# DWC_USB3 register map
Vendor: Texas Instruments
Peripheral module from a debugger description file (folder omap5430_ES2_PUBLIC).
Registers are 32-bit, read-write, reset 0x0 unless marked. A register's access mark holds for its fields unless they carry their own. Offsets are as the file gives them; lines under a group give offsets from that group; [hi:lo] are bit positions; {n}, {i} and the like mark numbered series; 'fields as' and 'values as' point back to an identical list; <NAME> marks a mode.

## DWC_USB3 (part 1 of 2)
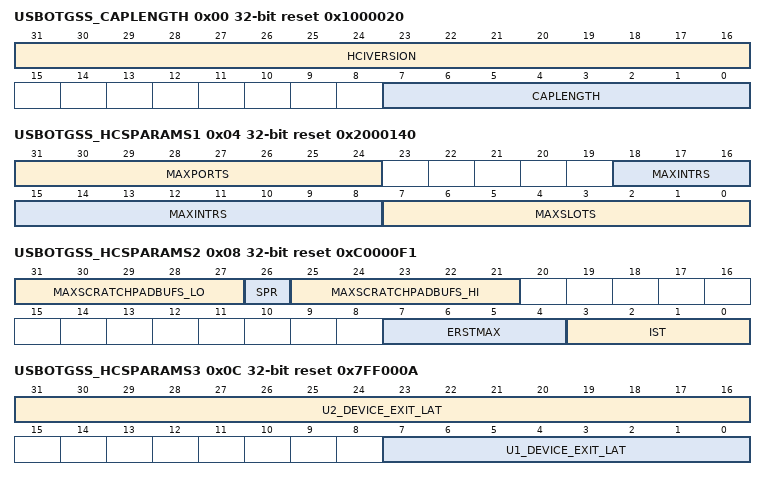
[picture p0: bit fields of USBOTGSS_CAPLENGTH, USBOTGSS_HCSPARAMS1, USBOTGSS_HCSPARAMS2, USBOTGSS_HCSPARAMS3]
0x00 USBOTGSS_CAPLENGTH ro reset 0x1000020 — Capability registers length + host controller interface (HCI) version number
  [31:16] HCIVERSION — Host Controller Interface Version (xHCI), in BCD. Set by USBOTGSS_FLADJ[29] XHCI_REVISION field.
    150=HCIVERSION_150_r (xHCI revision 0.96); 0x100=HCIVERSION_256_r (xHCI revision 1.0 + errata)
  [7:0] CAPLENGTH — Capability Register Length: length of the xHCI Capabilities registers bank, in bytes; also the offset of the xHCI Operational registers bank (starting withUSBOTGSS_USBCMD), with respect to xHCI base (i.e. the current register)
0x04 USBOTGSS_HCSPARAMS1 ro reset 0x2000140 — Host controller structural parameters 1 (xHCI)
  [31:24] MAXPORTS — See xHCI specification.
  [18:8] MAXINTRS — See xHCI specification.
  [7:0] MAXSLOTS — See xHCI specification.
0x08 USBOTGSS_HCSPARAMS2 ro reset 0xC0000F1 — Host controller structural parameters 2 (xHCI)
  [31:27] MAXSCRATCHPADBUFS_LO — Max Scratchpad Buffers, lower bits: See xHCI specification
  [26] SPR — Scratchpad Restore: See xHCI specification
    1=yes (Integrity of the scratchpad buffer required across power events); 0=no (Scratchpad buffers may be freed and reallocated between power events)
  [25:21] MAXSCRATCHPADBUFS_HI — Max Scratchpad Buffers, higher bits: see xHCI 1.0 standard
  [7:4] ERSTMAX — Event Ring Segment Table Max: See xHCI specification
  [3:0] IST — Isochronous Scheduling Threshold: See xHCI specification
0x0C USBOTGSS_HCSPARAMS3 ro reset 0x7FF000A — Host controller structural parameters 3 (xHCI)
  [31:16] U2_DEVICE_EXIT_LAT — U2 device exit latency: Worst-case latency to transition from U2 to U0, in µs. Applies to all root hub ports.
    0x7FF=U2_DEVICE_EXIT_LAT_2047_r (Less than 2047 µs (maximum: Greater values are reserved.)); 2=Less_than_2_µs; 1=Less_than_1_µs; 0=U2_DEVICE_EXIT_LAT_0_r (0)
  [7:0] U1_DEVICE_EXIT_LAT — U1 device exit latency: Worst-case latency to transition a root hub port link state (PLS) from U1 to U0, in µs.
    2=Less_than_2_µs; 1=Less_than_1_µs; 0=U1_DEVICE_EXIT_LAT_0_r (0); 10=U1_DEVICE_EXIT_LAT_10_r (Less than 10 µs (maximum: Greater values are reserved.))
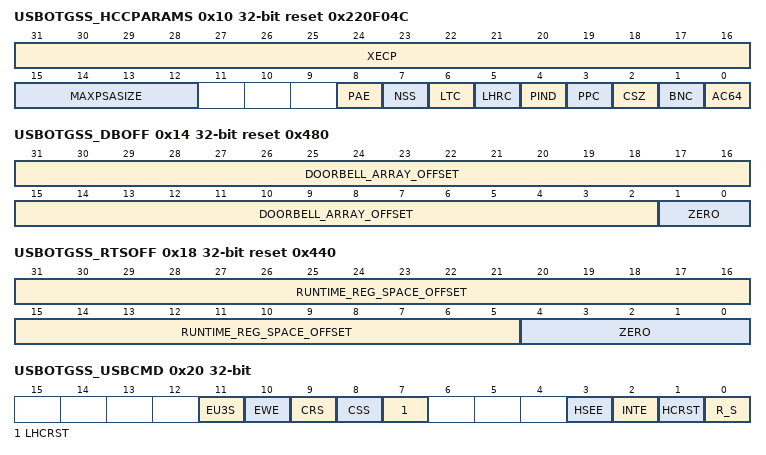
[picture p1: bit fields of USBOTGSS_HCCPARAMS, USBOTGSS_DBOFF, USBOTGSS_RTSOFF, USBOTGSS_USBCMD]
0x10 USBOTGSS_HCCPARAMS ro reset 0x220F04C — Host controller capability parameters (xHCI)
  [31:16] XECP — xHCI Extended Capabilties Pointer. 32-bit dword offset, with respect to xHCI base, of the first item of the capability list.
  [15:12] MAXPSASIZE — Maximum Primary Stream Array Size: See xHCI specification
  [8] PAE — Parse All Event data: see xHCI 1.0 standard w errata
  [7] NSS — No Secondary SID Support See xHCI specification
  [6] LTC — Latency Tolerance messaging Capability See xHCI specification
  [5] LHRC — Light HC Reset Capability: See xHCI specification
  [4] PIND — Port Indicators: See xHCI specification
  [3] PPC — Port Power Control: See xHCI specification
  [2] CSZ — Context Size: See xHCI specification
  [1] BNC — Bandwidth Negotiation Capability: See xHCI specification
  [0] AC64 — 64-bit Address Capability: See xHCI specification
0x14 USBOTGSS_DBOFF ro reset 0x480 — Doorbell offset (xHCI): Byte offset of the doorbell register array (, with respect to the xHCI base (that is, register)
  [31:2] DOORBELL_ARRAY_OFFSET — Byte address offset MSBs
  [1:0] ZERO — Byte address offset LSBs, always 0 (offset is 32-bit = 4-byte aligned)
0x18 USBOTGSS_RTSOFF ro reset 0x440 — RunTime space offset (xHCI): Byte offset of the runtime register bank (starting with), with respect to the xHCI base (that is, register)
  [31:5] RUNTIME_REG_SPACE_OFFSET — Byte address offset MSBs
  [4:0] ZERO — Byte address offset LSBs, always 0 (offset is 32-byte aligned)
0x20 USBOTGSS_USBCMD access per field — USB command register (xHCI)
  [11] EU3S rw — See xHCI specification.
  [10] EWE rw — See xHCI specification.
  [9] CRS rw — See xHCI specification.
  [8] CSS rw — See xHCI specification.
  [7] LHCRST rw — See xHCI specification.
  [3] HSEE rw — See xHCI specification.
  [2] INTE rw — See xHCI specification.
  [1] HCRST rw — See xHCI specification.
  [0] R_S rw — See xHCI specification.
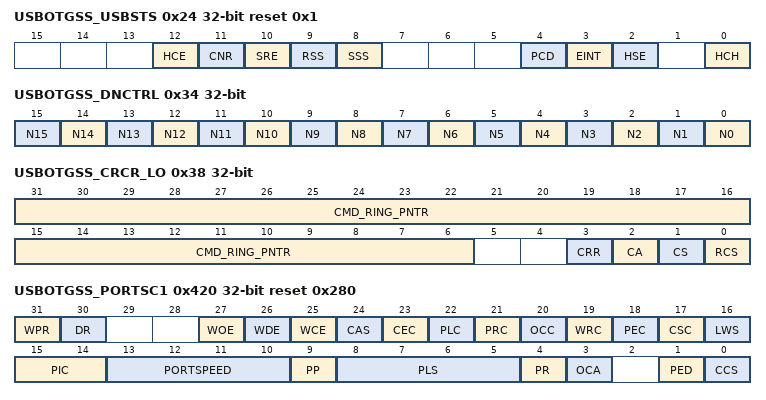
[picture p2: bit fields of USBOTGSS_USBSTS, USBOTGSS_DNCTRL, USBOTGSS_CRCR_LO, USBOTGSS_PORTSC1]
0x24 USBOTGSS_USBSTS access not given reset 0x1 — USB status register (xHCI)
  [12] HCE ro — See xHCI specification.
  [11] CNR ro — Controller not ready (see xHCI specification). Runtime or other operational registers are not accessed until field is cleared. Beyond xHCI (that is, USB host mode) functionality, indicates when the reset of the RAM is accessible, which makes the RAM-mapped registers accessible.
    1=not_ready (Controller not ready); 0=ready (Controller ready, RAM-mapped registers accessible)
  [10] SRE — See xHCI specification. (access RW W1toClr)
  [9] RSS ro — See xHCI specification.
  [8] SSS ro — See xHCI specification.
  [4] PCD — See xHCI specification. (access RW W1toClr)
  [3] EINT — See xHCI specification. (access RW W1toClr)
  [2] HSE — See xHCI specification. (access RW W1toClr)
  [0] HCH ro — See xHCI specification.
0x28 USBOTGSS_PAGESIZE ro reset 0x1 — Page size register (xHCI)
  [15:0] PAGE_SIZE — See xHCI specification. When bit n is set to 1, a page size of 2^(n+12) is supported.
    1=4-KiB_page_supported
0x34 USBOTGSS_DNCTRL — Device notification control register (xHCI)
  [n] N{n} (n=0..15) — See xHCI specification.
0x38 USBOTGSS_CRCR_LO — Command ring control register, lower half (xHCI)
  [31:6] CMD_RING_PNTR — See xHCI specification.
  [3] CRR — See xHCI specification.
  [2] CA — See xHCI specification.
  [1] CS — See xHCI specification.
  [0] RCS — See xHCI specification.
0x3C USBOTGSS_CRCR_HI — Command ring control register, upper half (xHCI)
  [31:0] CMD_RING_PNTR — See xHCI specification.
0x50 USBOTGSS_DCBAAP_LO — Device context base address array pointer, lower half (xHCI)
  [31:6] DEVICE_CONTEXT_BAAP — See xHCI specification.
0x54 USBOTGSS_DCBAAP_HI — Device context base address array pointer, upper half (xHCI)
  [31:0] DEVICE_CONTEXT_BAAP — See xHCI specification.
0x58 USBOTGSS_CONFIG — Configure (xHCI)
  [7:0] MAXSLOTSEN — See xHCI specification.
0x420 USBOTGSS_PORTSC1 access not given reset 0x280 — Port 1 (USB2) status and control (xHCI)
  [31] WPR — See xHCI specification (access RW W1toSet)
  [30] DR ro — See xHCI specification
  [27] WOE rw — See xHCI specification
  [26] WDE rw — See xHCI specification
  [25] WCE rw — See xHCI specification
  [24] CAS ro — See xHCI specification
  [23] CEC — See xHCI specification (access RW W1toClr)
  [22] PLC — See xHCI specification (access RW W1toClr)
  [21] PRC — See xHCI specification (access RW W1toClr)
  [20] OCC — See xHCI specification (access RW W1toClr)
  [19] WRC — See xHCI specification (access RW W1toClr)
  [18] PEC — See xHCI specification (access RW W1toClr)
  [17] CSC — See xHCI specification (access RW W1toClr)
  [16] LWS rw — See xHCI specification
  [15:14] PIC rw — See xHCI specification
  [13:10] PORTSPEED ro — See xHCI specification
  [9] PP rw — See xHCI specification
  [8:5] PLS rw — See xHCI specification
  [4] PR — See xHCI specification (access RW W1toSet)
  [3] OCA ro — See xHCI specification
  [1] PED — See xHCI specification (access RW W1toClr)
  [0] CCS ro — See xHCI specification
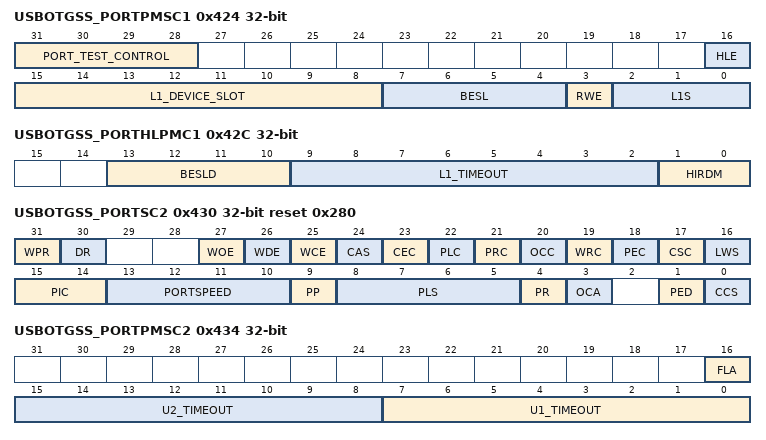
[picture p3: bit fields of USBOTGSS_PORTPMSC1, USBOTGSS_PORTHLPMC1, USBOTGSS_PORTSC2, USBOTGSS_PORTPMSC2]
0x424 USBOTGSS_PORTPMSC1 access per field — Port 1 (USB2) Power mManagement status and control (xHCI) Note that the PMSC register makeup is protocol-dependent (here: USB2)
  [31:28] PORT_TEST_CONTROL rw — See xHCI specification
  [16] HLE rw — See xHCI specification
  [15:8] L1_DEVICE_SLOT rw — See xHCI specification
  [7:4] BESL rw — See xHCI 1.0 standard w. errata
  [3] RWE rw — See xHCI specification
  [2:0] L1S ro — See xHCI specification
0x428 USBOTGSS_PORTLI1 ro — Port 1 (USB2) link info (xHCI)
  [15:0] LINK_ERROR_COUNT — See xHCI specification.
0x42C USBOTGSS_PORTHLPMC1 access per field — Port 1 (USB2) Hardware LPM Control (xHCI) Field structure is protocol-dependent (here: USB3)
  [13:10] BESLD rw — See xHCI 1.0 standard w errata
  [9:2] L1_TIMEOUT rw — See xHCI 1.0 standard w errata
  [1:0] HIRDM rw — See xHCI 1.0 standard w errata
0x430 USBOTGSS_PORTSC2 access not given reset 0x280 — Port 2 (USB3) status and control (xHCI)
  fields as USBOTGSS_PORTSC1
0x434 USBOTGSS_PORTPMSC2 access per field — Port 2 (USB3) power management (LPM) status and control (xHCI) Note that the PMSC register makeup is protocol-dependent (here: USB3)
  [16] FLA rw — See xHCI specification
  [15:8] U2_TIMEOUT rw — See xHCI specification
  [7:0] U1_TIMEOUT rw — See xHCI specification
0x438 USBOTGSS_PORTLI2 ro — Port 2 (USB3) link info (xHCI)
  [15:0] LINK_ERROR_COUNT — See xHCI specification.
0x43C USBOTGSS_PORTHLPMC2 ro — Port 2 (USB3) Hardware LPM Control (xHCI) Field structure is protocol-dependent (here: USB3)
0x440 USBOTGSS_MFINDEX ro — Microframe index (xHCI)
  [13:0] MICROFRAME_INDEX — See xHCI specification.
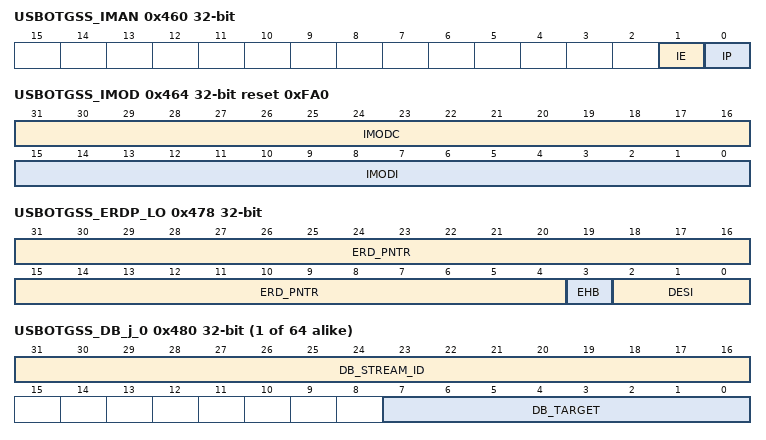
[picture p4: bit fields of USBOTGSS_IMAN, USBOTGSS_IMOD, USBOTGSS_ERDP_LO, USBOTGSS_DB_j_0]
0x460 USBOTGSS_IMAN access not given — Interrupter Management (xHCI)
  [1] IE rw — Interrupt enable
    0=Interrupt_disabled; 1=Interrupt_enabled
  [0] IP — Interrupt pending. Set (to 1) when: IE = 1,USBOTGSS_IMOD[31:16] IMODC = 0, the associated event ring is not empty, USBOTGSS_ERDP_LO[3] EHB = 0. (access RW W1toClr)
    0=No_IRQ_pending; 1=IRQ_pending
0x464 USBOTGSS_IMOD reset 0xFA0 — Interrupter moderation (xHCI)
  [31:16] IMODC — Interrupt moderation counter: Loaded to IMODI whenever IP is cleared to 0, counts down to 0, and stops. IRQ is generated when counter is 0, event ring is not empty, USBOTGSS_IMAN[1] IE = 1, USBOTGSS_IMAN[0] IP = 1, USBOTGSS_ERDP_LO[3] EHB = 0. Can be directly written to at any time alter the interrupt rate
  [15:0] IMODI — Interrupt moderation interval: Minimum inter-IRQ interval, in 250-ns increments.
    0xFA0=1-ms_interval_(default); 0=IRQ_0 (IRQ throttling disabled: IRQs generated immediately.); 1=250-ns_minimum_interval
0x468 USBOTGSS_ERSTSZ — Event ring segment table size (xHCI)
  [15:0] ERS_TABLE_SIZE — See xHCI specification.
0x470 USBOTGSS_ERSTBA_LO — Event ring segment table base address, lower half (xHCI)
  [31:6] ERS_TABLE_BAR — See xHCI specification.
0x474 USBOTGSS_ERSTBA_HI — Event ring segment table base address, upper half (xHCI)
  [31:0] ERS_TABLE_BAR — See xHCI specification.
0x478 USBOTGSS_ERDP_LO access not given — Event ring dequeue pointer, lower half (xHCI)
  [31:4] ERD_PNTR rw — See xHCI specification.
  [3] EHB — See xHCI specification. (access RW W1toClr)
  [2:0] DESI rw — See xHCI specification.
0x47C USBOTGSS_ERDP_HI — Event ring dequeue pointer, upper half (xHCI)
  [31:0] ERD_PNTR — See xHCI specification.
{0x480+4i} USBOTGSS_DB_j_{i} access per field (i=0..63) — Doorbell (xHCI)
  [31:16] DB_STREAM_ID rw — See xHCI specification.
  [7:0] DB_TARGET rw — See xHCI specification.
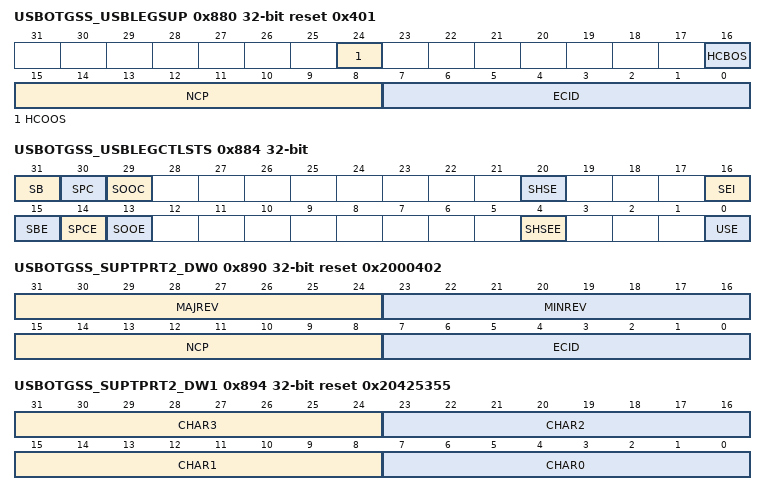
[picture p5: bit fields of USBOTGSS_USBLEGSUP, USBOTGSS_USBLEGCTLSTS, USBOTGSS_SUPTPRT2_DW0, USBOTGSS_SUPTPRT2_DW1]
0x880 USBOTGSS_USBLEGSUP access per field reset 0x401 — USB legacy support capability
  [24] HCOOS rw — HC OS Owned Semaphore: See xHCI specification
  [16] HCBOS rw — HC BIOS Owned Semaphore: See xHCI specification
  [15:8] NCP ro — Next Capability Pointer: 32-bit dword offset of the next capability.
    0=eol (End of capability list)
  [7:0] ECID ro — Extended Capability ID code (descriptor size, in bytes)
    2=prot (Supported protocol: MajRev.MinRev (12)); 1=legacy (USB legacy support (8)); 10=dbc (USB debug capability (56))
0x884 USBOTGSS_USBLEGCTLSTS access not given — USB legacy control/status
  [31] SB — See xHCI specification. (access RW W1toClr)
  [30] SPC — See xHCI specification. (access RW W1toClr)
  [29] SOOC — See xHCI specification. (access RW W1toClr)
  [20] SHSE ro — See xHCI specification.
  [16] SEI ro — See xHCI specification.
  [15] SBE rw — See xHCI specification.
  [14] SPCE rw — See xHCI specification.
  [13] SOOE rw — See xHCI specification.
  [4] SHSEE rw — See xHCI specification.
  [0] USE rw — See xHCI specification.
0x890 USBOTGSS_SUPTPRT2_DW0 ro reset 0x2000402 — Supported protocol capability USB2, 32-bit dword 0
  [31:24] MAJREV — Major Revision, BCD-encoded
  [23:16] MINREV — Minor Revision, BCD-encoded
  [15:8] NCP — Next Capability Pointer: 32-bit dword offset of the next capability.
    0=eol (End of capability list)
  [7:0] ECID — Extended Capability ID code (descriptor size, in bytes)
    values as USBOTGSS_USBLEGSUP.ECID
0x894 USBOTGSS_SUPTPRT2_DW1 ro reset 0x20425355 — Supported protocol capability USB2, 32-bit dword 1: Name String 'USB '
  [31:24] CHAR3 — ASCII ' ' (space)
  [23:16] CHAR2 — ASCII 'B'
  [15:8] CHAR1 — ASCII 'S'
  [7:0] CHAR0 — ASCII 'U'
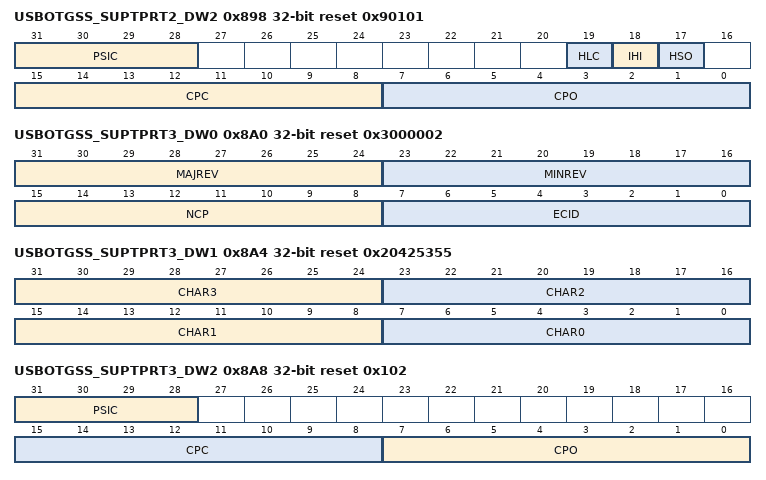
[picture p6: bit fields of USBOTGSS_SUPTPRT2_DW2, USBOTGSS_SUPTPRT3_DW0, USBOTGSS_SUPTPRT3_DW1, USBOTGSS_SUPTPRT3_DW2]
0x898 USBOTGSS_SUPTPRT2_DW2 ro reset 0x90101 — Supported protocol capability USB2, 32-bit dword 2
  [31:28] PSIC — Port Speed ID Count. Reserved in xHCI 0.96
    0=all (USB2 High/Full/Low-speeds supported)
  [19] HLC — Hardware LPM Capability.
  [18] IHI — Integrated Hub Implemented.
  [17] HSO — High-Speed Only
  [15:8] CPC — Compatible Port Count: Number of consecutive ports of the root hub that support this protocol, from CPO to CPO+CPC-1
  [7:0] CPO — Compatible Port Offset: Starting port number of root hub port(s) that support this protocol.
0x89C USBOTGSS_SUPTPRT2_DW3 ro — Supported protocol capability USB2, 32-bit dword 3
  [4:0] PST — Protocol Slot Type, see xHCI 1.0 standard w errata
0x8A0 USBOTGSS_SUPTPRT3_DW0 ro reset 0x3000002 — Supported protocol capability USB3, 32-bit dword 0
  fields as USBOTGSS_SUPTPRT2_DW0
0x8A4 USBOTGSS_SUPTPRT3_DW1 ro reset 0x20425355 — Supported protocol capability USB3, 32-bit dword 1: Name String 'USB '
  fields as USBOTGSS_SUPTPRT2_DW1
0x8A8 USBOTGSS_SUPTPRT3_DW2 ro reset 0x102 — Supported protocol capability USB3, 32-bit dword 2
  [31:28] PSIC — Port Speed ID Count. Reserved in xHCI 0.96
    0=ss (USB3 Super-Speed supported)
  [15:8] CPC — Compatible Port Count: Number of consecutive ports of the root hub that support this protocol, from CPO to CPO+CPC-1
  [7:0] CPO — Compatible Port Offset: Starting port number of root hub port(s) that support this protocol.
0x8AC USBOTGSS_SUPTPRT3_DW3 ro — Supported protocol capability USB3, 32-bit dword 3
  [4:0] PST — Protocol Slot Type, see xHCI 1.0 standard w errata
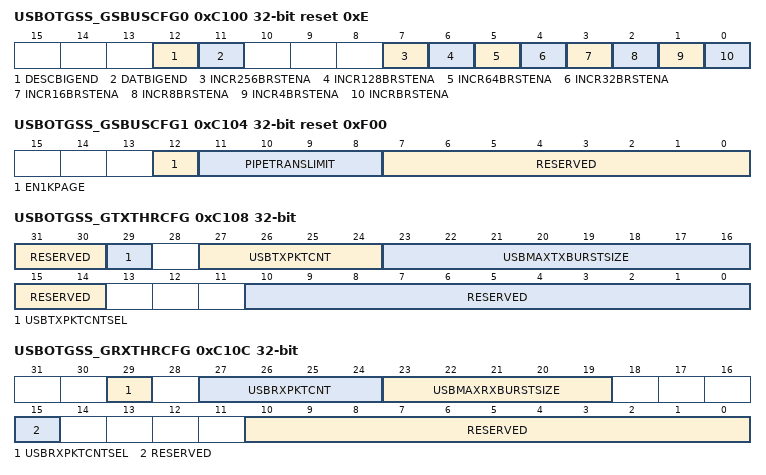
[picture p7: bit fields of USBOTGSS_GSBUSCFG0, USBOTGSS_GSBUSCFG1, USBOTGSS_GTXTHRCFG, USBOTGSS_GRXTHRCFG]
0xC100 USBOTGSS_GSBUSCFG0 reset 0xE — Global device Bus Configuration Register 0
  [12] DESCBIGEND — Endian mode for descriptor accesses.
    0=Little-Endian (default); 1=big (Big-Endian)
  [11] DATBIGEND — Endian mode for data accesses.
    0=Little-Endian (default); 1=big (Big-Endian)
  [7] INCR256BRSTENA — INCR256 Burst Type Enable. 256×64/8= 2-kByte burst.
  [6] INCR128BRSTENA — INCR128 Burst Type Enable. 128×64/8= 1-kByte burst.
  [5] INCR64BRSTENA — INCR64 Burst Type Enable. 64×64/8= 512-Byte burst.
  [4] INCR32BRSTENA — INCR32 Burst Type Enable. 32×64/8= 256-Byte burst.
  [3] INCR16BRSTENA — INCR16 Burst Type Enable. 16×64/8= 128-Byte burst.
  [2] INCR8BRSTENA — INCR8 Burst Type Enable. 8×64/8= 64-Byte burst.
  [1] INCR4BRSTENA — INCR4 Burst Type Enable. 4×64/8= 32-Byte burst: RECOMMENDED Enables bursts of beat length 1, 2, 3, 4, and prevents (16-byte) descriptor accesses from being broken up: highly recommended.
  [0] INCRBRSTENA — Undefined Length INCR Burst Type Enable: DO NOT ENABLE When enabled, this has higher priority than other burst types.
0xC104 USBOTGSS_GSBUSCFG1 access per field reset 0xF00 — Global device bus configuration register 1
  [12] EN1KPAGE rw — 1k-page boundary enable
    0=Master breaks requests only on 4-KiB boundaries; 1=Master breaks requests on all 1-KiB boundaries
  [11:8] PIPETRANSLIMIT rw — Maximum number of outstanding (read or write) pipelined sequential (i.e. in-order) transaction requests on the master interface (field value+1)
    15=Up_to_16_pending_requests_(maximum); 0=Single_request_mode; 1=Up_to_2_pending_requests
  [7:0] RESERVED rw — Always write 0. (The result of writing a non-0 value is undetermined.)
0xC108 USBOTGSS_GTXTHRCFG access per field — Global TX threshold control register. Valid only in Host mode.
  [31:30] RESERVED rw — Always write 0, result of writing of a non-zero value is undetermined.
  [29] USBTXPKTCNTSEL rw — USB Transmit Packet Count Enable: Enables/disables USB trasnmission multi-packet thresholding
    0=dis (Disabled: Transmission is only started on the USB after the entire packet has been fetched into the corresponding TXFIFO. Rest of the register must be all-zero.); 1=en (Enabled: USB transmission is started only after USB Transmit Packet Count amount of packets for the USB transaction (burst) are already in the corresponding TXFIFO This mode is only valid in the host, superspeed mode.)
  [27:24] USBTXPKTCNT rw — USB Transmit Packet Count : Number of packets that must be in the TXFIFO before transmission for the corresponding USB transaction (burst) can start. Don't care if USBTXPKTCNTSEL=0.
    15=max (Maximum value); 0=dis (Use when and only when disabled (USBTXPKTCNTSEL=0)); 1=min (Minimum value (when enabled))
  [23:16] USBMAXTXBURSTSIZE rw — USB Maximum Transmit Burst Size. Max OUT burst size, when USBTXPKTCNTSEL=1. Avoids TX FIFO underrun when the system bus is slower than the USB. Only applies to SS Bulk / Iso / Int OUT endpoints in host mode. Don't care if USBTXPKTCNTSEL=0.
    0=dis (Use when and only when disabled (USBTXPKTCNTSEL=0)); 1=min (Burst of up to 1 (minimum value when enabled)); 16=max (Burst of up to 16 (maximum value))
  [15:14] RESERVED rw — Always write 0, result of writing of a non-zero value is undetermined.
  [10:0] RESERVED rw — Always write 0, result of writing of a non-zero value is undetermined.
0xC10C USBOTGSS_GRXTHRCFG access per field — Global RX Threshold Control Register
  [29] USBRXPKTCNTSEL rw — USB ReceivePacket Count Enable Enables/disables USB reception multi-packet thresholding
    0=dis (The core can only start reception on the USB when the RX FIFO has space for at least one packet. Rest of the register must be all-zero.); 1=en (The core can only start reception on the USB when the RX FIFO has space for at least packet. This mode is only valid in the host mode. It is only used for SuperSpeed.)
  [27:24] USBRXPKTCNT rw — USB Receive Packet Count: Number of packets that must be available in the RX FIFO before the core can start the corresponding USB RX transaction (burst). Don't care if USBRXPKTCNTSEL=0.
    15=max (Maximum value); 0=dis (Use when and only when disabled (USBRXPKTCNTSEL=0)); 1=min (Minimum value (when enabled))
  [23:19] USBMAXRXBURSTSIZE rw — USB Maximum Receive Burst Size. Maxi IN burst size, when USBRXPKTCNTSEL = 1. When the system bus is slower than the USB, RX FIFO can overrun during a long burst. User can program a smaller value to this field to limit the RX burst size that the core can do. Only applies to SS Bulk / Iso / Int IN endpoints in host mode. Don't care if USBRXPKTCNTSEL=0.
    0=dis (Use when and only when disabled (USBRXPKTCNTSEL=0)); 1=min (Burst of up to 1 (minimum value when enabled)); 16=max (Burst of up to 16 (maximum value))
  [15] RESERVED rw — Always write 0, result of writing of a non-zero value is undetermined.
  [10:0] RESERVED rw — Always write 0, result of writing of a non-zero value is undetermined.
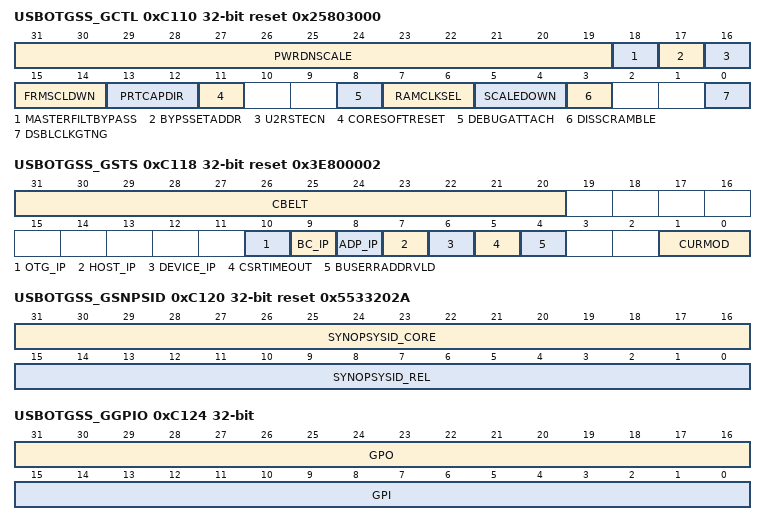
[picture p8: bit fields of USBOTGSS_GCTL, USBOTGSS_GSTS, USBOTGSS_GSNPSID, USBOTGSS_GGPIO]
0xC110 USBOTGSS_GCTL access per field reset 0x25803000 — Global control register
  [31:19] PWRDNSCALE rw — Power Down Scale: In P3 state, pipe clock stops and is replaced internally by the suspend clock to create a 16kHz reference. Set field to Fs/16k, rounded up, with Fp suspend clock frequency. Required accuracy is 0-50%
    2=32k_min (32kHz suspend clock (minimum frequency)); 0x960=38M4 (38.4 MHz suspend clock); 0x2EE=12 MHz suspend clock; 0x5DC=24 MHz suspend clock; 0x4B0=19M2 (19.2 MHz suspend clock); 0x32D=13 MHz suspend clock; 0x659=26 MHz suspend clock; 0x1E85=125 MHz suspend clock
  [18] MASTERFILTBYPASS rw — Master Filter Bypass. Bypasses the double-synchronizers and the 5 ms debounce filters on UTMI+ inputs (the latter are not implemented).
  [17] BYPSSETADDR rw — Override of the device address, bypassing the SET ADDRESS control transfer. For simulation only.
    0=Functional mode; 1=bypass (Device's address set directly to[9:3] DEVADDR)
  [16] U2RSTECN rw — If the super speed connection fails during POLL or LMP exchange, the device connects at non-SS mode. If this bit is set, then device attempts three more times to connect at SS, even if it previously failed to operate in SS mode.
  [15:14] FRMSCLDWN rw — Frame scale-down This field scales down device view of a SOF (FS/LS) / uSOF (HS) / ITP (SS) duration.
    0=SS/HS interval=125 us, FS interval=1ms (standard); 1=SS/HS interval=62.5 us, FS interval=0.5ms; 3=SS/HS interval=15.625 us, FS interval=0.125ms; 2=SS/HS interval=31.25 us, FS interval=0.25ms
  [13:12] PRTCAPDIR rw — Port Capability Direction
    1=hst (Core acts as DRD in host mode); 3=drd (Core acts as OTG DRD, with the mode set by the ID); 2=dev (Core acts as DRD in device mode)
  [11] CORESOFTRESET rw — Core Soft Reset. When you reset PHYs (using USBOTGSS_GUSB2PHYCFG or USBOTGSS_GUSB3PIPECTL registers), you must keep the core in reset state until PHY clocks are stable.
    0=no (No soft reset); 1=reset (Soft reset to core)
  [8] DEBUGATTACH rw — Debug Attach. When this bit is set: a) SS Link proceeds directly to the Polling link state (after RUN/STOP in the USBOTGSS_DCTL register is asserted) without checking remote termination. b) Link LFPS polling timeout is infinite c) Polling timeout during TS1 is infinite (in case link is waiting for TXEQ to finish).
  [7:6] RAMCLKSEL rw — RAM Clock Select. No action, hardware always uses bus clock (config 2'b00)
    0=bus (AXI bus clock); 1=PIPE clock; 3=mac (MAC clock (125 MHz)); 2=pipe_50 (PIPE/2 clock)
  [5:4] SCALEDOWN rw — Scale-Down Mode Enable Switches to shorter, non-standard protocol time intervals to speed up simulation. DO NOT MODIFY ON ACTUAL HARDWARE.
    0=none (Disable scale-downs. Legal USB timing values are used. Always use on actual hardware.); 1=Enables scaled down values of : - HS/FS/LS: all except Device-mode suspend and resume. - SS: Number of TxEq training sequences reduce to 8 - SS: LFPS polling burst time reduce to 100 ns - SS: LFPS warm reset receive reduce to 30 us - SS: more ...; 3=SS/HS/FS/LS: scale down all the above; 2=HS/FS/LS: scale-down of Device-mode suspend and resume. SS: No TxEq training sequences are sent.
  [3] DISSCRAMBLE rw — Disable Scrambling. Transmit request to Link Partner on next transition to Recovery or Polling.
  [0] DSBLCLKGTNG rw — Disable Clock Gating. When this bit is set to 1 and the core is in Low Power mode, internal clock gating is disabled.
0xC118 USBOTGSS_GSTS access per field reset 0x3E800002 — Global status register
  [31:20] CBELT ro — Current BELT Value In Host mode, this field indicates the minimum value of all received device BELT values and the BELT value that is set by the Set Latency Tolerance Value command.
  [10] OTG_IP ro — OTG interrupt status
    1=pend (Interrupt pending); 0=none (No interrupt pending)
  [9] BC_IP ro — Battery Charger interrupt status: NOT IMPLEMENTED
  [8] ADP_IP ro — ADP interrupt status: NOT IMPLEMENTED
  [7] HOST_IP ro — Host interrupt status
    1=pend (Interrupt pending); 0=none (No interrupt pending)
  [6] DEVICE_IP ro — Device interrupt status
    1=pend (Interrupt pending); 0=none (No interrupt pending)
  [5] CSRTIMEOUT rw — Control/Status Register access Timeout status flag.
    0=noaction; 1=Clear the status flag; 1=set (CSR access timed out after 65,535 clock cycles); 0=noevent (no CSR timeout)
  [4] BUSERRADDRVLD rw — Bus Error Address Valid status flag. Also flagged onUSBOTGSS_USBSTS[2] HSE field (host mode) and DEPEVT[12] on XferComplete/XferInProgress event (device mode).
    0=noaction; 1=Clear the status flag; 1=set (At least one bus error took place, the first one near address GBUSERRADDR.); 0=noevent (No bus error since last clear; GBUSERRADDR is not valid)
  [1:0] CURMOD ro — Current Mode of Operation.
    2=drd; 1=host; 0=dev (Device)
0xC120 USBOTGSS_GSNPSID ro reset 0x5533202A — Synopsys ID: Core identification and release number. Software uses this register to configure release-specific features in the driver.
  [31:16] SYNOPSYSID_CORE — SYNOPSYSID MSBytes: core identifier
    0x5533=id (ASCII for 'U3' = DWC_USB3)
  [15:0] SYNOPSYSID_REL — SYNOPSYSID LSBytes: version number For instance, version 1.00a =&gt; 0x100A
    0x183A=1_83a (version 1.83a); 0x202A=2_02a (version 2.02a)
0xC124 USBOTGSS_GGPIO access per field — Global general-purpose input/output register
  [31:16] GPO rw — General-purpose output. DO NOT USE: NOT CONNECTED.
  [15:0] GPI ro — General-purpose inputs. TIED LOW.
0xC128 USBOTGSS_GUID — Global user ID register
  [31:0] USERID — Application-programmable ID field
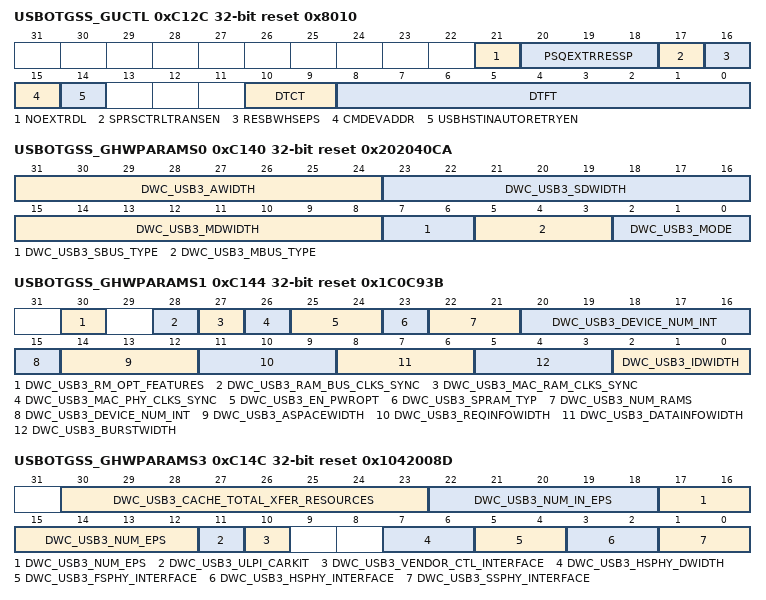
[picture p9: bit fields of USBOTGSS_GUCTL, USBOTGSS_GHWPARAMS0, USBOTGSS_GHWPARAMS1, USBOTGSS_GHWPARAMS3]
0xC12C USBOTGSS_GUCTL reset 0x8010 — Global user control register
  [21] NOEXTRDL — No Extra Delay between SOF and the 1st packet (when host)
    0=dis (2 us delay between SOF and first packet. Some bandwith is lost.); 1=en (No extra delay. May cause some devices to misbehave.)
  [20:18] PSQEXTRRESSP — Protocol Status Queue Extra Reserved Space (Debug only). Additional space in the PSQ reserved before the USB3 protocl transaction layer (U3PTL) initiates a new USB transaction and burst beats.
    0=dis; 1=en
  [17] SPRSCTRLTRANSEN — Sparse Control Transaction Enable. Valid in host mode only (any speed).
    0=dis (Feature disabled, no limitation on control transactions); 1=en (Host controller schedules transactions for Control transfer in different [micro]frames to prevent incorrect behaviour from device.)
  [16] RESBWHSEPS — Reserving (more) Bandwidth for HS Periodic EPs. Valid in host mode only.
    0=HC reserves 80% of the bandwidth for periodic EPs; 1=HC reserves 85% of the bandwidth for periodic EPs, which allows 2 high speed, high bandwidth ISOC EPs
  [15] CMDEVADDR — Compliance Mode for Device Address. Valid in host mode only.
    0=eq (Device Address is equal to Slot ID.); 1=diff (Increment Device Address on each Address Device command. Slot ID may have different value than Device Address if max_slot_enabled < 128.)
  [14] USBHSTINAUTORETRYEN — Host IN Auto Retry Enable: host core behaviour upon data packet CRC errors or internal overrun scenarios in non-isochronous IN transfers.
    0=dis (Auto Retry Disabled: Host core to reply with a terminating retry ACK (Retry=1 and NumP=0)); 1=en (Auto Retry Enabled: Host core to reply with a non-terminating retry ACK (Retry=1 and NumP!=0))
  [10:9] DTCT — Device Timeout Coarse Tuning: time the host waits for a response from device before timeout. Coarse setting.
    0=fine (Use DTFT instead); 1=0m5 (500 us); 3=5ms (6.5 ms); 2=1m5 (1.5 ms)
  [8:0] DTFT — Device Timeout Fine Tuning: time the host waits for a response from device before timeout. Fine setting. Timer runs on the 125 MHz clock (8 ns period), timeout is DTFT × 256 × 8 ns ~= DTFT × 2 us Don't care unless DTCT=0
    1=2us (~ 2 us timeout (2,048 ns)); 125=256 us timeout (maximum, exact value); 50=~ 100 us timeout (102,400 ns); 5=~ 10 us timeout (10,240 ns)
0xC130 USBOTGSS_GBUSERRADDRLO ro — Global Bus Error (non-precise) Address, LSbits: Base address of the first system bus DMA transfer that got a bus error. Note that each DMA transfer can contain several bursts, each spanning several addresses. Valid when the[4] BUSERRADDRVLD field is 1. Cleared upon core reset.
  [31:0] BUSERRADDRLO — BUSERRADDR[31:0]
0xC134 USBOTGSS_GBUSERRADDRHI ro — Global Bus Error (non-precise) Address, MSbits: Base address of the first system bus DMA transfer that got a bus error. Note that each DMA transfer can contain several bursts, each spanning several addresses. Valid when the[4] BUSERRADDRVLD field is 1. Cleared upon core reset.
  [31:0] BUSERRADDRHI — BUSERRADDR[63:32]
0xC138 USBOTGSS_GPRTBIMAPLO access per field — Global port-to-SS USB instance mapping, low bits [31:0]
  [3:0] BINUM1 rw — SS USB instance number for port number 1 Application-programmable ID field
0xC13C USBOTGSS_GPRTBIMAPHI ro — Global Port-to-SS USB Instance Mapping, high bits [63:32]
0xC140 USBOTGSS_GHWPARAMS0 ro reset 0x202040CA — Global hardware parameters 0
  [31:24] DWC_USB3_AWIDTH — Global hardware configuration parameter DWC_USB3_AWIDTH: (Master) Address Width (in bits)
  [23:16] DWC_USB3_SDWIDTH — Global hardware configuration parameter DWC_USB3_SDWIDTH: Slave Data Width (in bits)
  [15:8] DWC_USB3_MDWIDTH — Global hardware configuration parameter DWC_USB3_MDWIDTH: Master Data Width (in bits)
  [7:6] DWC_USB3_SBUS_TYPE — Global hardware configuration parameter DWC_USB3_SBUS_TYPE: (System bus) Slave type
    0=Native slave
  [5:3] DWC_USB3_MBUS_TYPE — Global hardware configuration parameter DWC_USB3_MBUS_TYPE: (System bus) Master type
    1=axi (AXI (AMBA 3) master system bus)
  [2:0] DWC_USB3_MODE — Global hardware configuration parameter DWC_USB3_MODE
    2=drd (Dual-role device (DRD) i.e. both device and host); 1=hst (Host-only); 0=dev (Device-only)
0xC144 USBOTGSS_GHWPARAMS1 ro reset 0x1C0C93B — Global hardware parameters 1
  [30] DWC_USB3_RM_OPT_FEATURES — Global hardware configuration parameter DWC_USB3_RM_OPT_FEATURES: Remove Optional Features
    1=yes; 0=no
  [28] DWC_USB3_RAM_BUS_CLKS_SYNC — Global hardware configuration parameter DWC_USB3_RAM_BUS_CLKS_SYNC: RAM vs. BUS clocks synchronous ?
    1=yes; 0=no
  [27] DWC_USB3_MAC_RAM_CLKS_SYNC — Global hardware configuration parameter DWC_USB3_MAC_RAM_CLKS_SYNC: MAC vs. RAM clocks synchronous ?
    1=yes; 0=no
  [26] DWC_USB3_MAC_PHY_CLKS_SYNC — Global hardware configuration parameter DWC_USB3_MAC_PHY_CLKS_SYNC: MAC vs. PHY clocks synchronous ?
    1=yes; 0=no
  [25:24] DWC_USB3_EN_PWROPT — Global hardware configuration parameter DWC_USB3_EN_PWROPT: Power optimization
    2=clock_hibernation; 1=clock; 0=none
  [23] DWC_USB3_SPRAM_TYP — Global hardware configuration parameter DWC_USB3_SPRAM_TYP
    1=SP (Single-port RAM)
  [22:21] DWC_USB3_NUM_RAMS — Global hardware configuration parameter DWC_USB3_NUM_RAMS: Number of internal RAMs
    3=DWC_USB3_NUM_RAMS_3_r (Three-RAM); 2=DWC_USB3_NUM_RAMS_2_r (Two-RAM); 1=DWC_USB3_NUM_RAMS_1_r (Single-RAM)
  [20:15] DWC_USB3_DEVICE_NUM_INT — Global hardware configuration parameter DWC_USB3_DEVICE_NUM_INT: Number of interrupts (and event buffers) in device mode
  [14:12] DWC_USB3_ASPACEWIDTH — Global hardware configuration parameter DWC_USB3_ASPACEWIDTH
  [11:9] DWC_USB3_REQINFOWIDTH — Global hardware configuration parameter DWC_USB3_REQINFOWIDTH
  [8:6] DWC_USB3_DATAINFOWIDTH — Global hardware configuration parameter DWC_USB3_DATAINFOWIDTH
  [5:3] DWC_USB3_BURSTWIDTH — Global hardware configuration parameter DWC_USB3_BURSTWIDTH minus one, fixed to 8-1=7
  [2:0] DWC_USB3_IDWIDTH — Global hardware configuration parameter DWC_USB3_IDWIDTH minus 1 Note: Sets only the master port's ID width. Slave ID width is set by non-readable DWC_USB3_SIDWIDTH
0xC148 USBOTGSS_GHWPARAMS2 ro — Global hardware parameters 2
  [31:0] DWC_USB3_USERID — Global hardware configuration parameter DWC_USB3_USERID
0xC14C USBOTGSS_GHWPARAMS3 ro reset 0x1042008D — Global hardware parameters 3
  [30:23] DWC_USB3_CACHE_TOTAL_XFER_RESOURCES — Global hardware configuration parameter DWC_USB3_NUM_CACHE_TOTAL_XFER_RESOURCES: Cache total transfer resources
  [22:18] DWC_USB3_NUM_IN_EPS — Global hardware configuration parameter DWC_USB3_NUM_IN_EPS: Number of IN endpoints, with EP0 counting as one.
  [17:12] DWC_USB3_NUM_EPS — Global hardware configuration parameter DWC_USB3_NUM_EPS: Total number of endpoints (IN+OUT, with EP0 counting as 2 separate ones)
  [11] DWC_USB3_ULPI_CARKIT — Global hardware configuration parameter DWC_USB3_ULPI_CARKIT: ULPI (optional) car-kit mode implementation
    1=vc (CK mode implemented); 0=no (CK mode not implemented)
  [10] DWC_USB3_VENDOR_CTL_INTERFACE — Global hardware configuration parameter DWC_USB3_VENDOR_CTL_INTERFACE: (UTMI) Vendor Control i/f implementation
    1=vc (VC i/f implemented); 0=no (VC i/f not implemented)
  [7:6] DWC_USB3_HSPHY_DWIDTH — Global hardware configuration parameter DWC_USB3_HSPHY_DWIDTH: HS PHY data width
    2=DWC_USB3_HSPHY_DWIDTH_2_r (8/16 bit UTMI @60/30 MHz); 1=DWC_USB3_HSPHY_DWIDTH_1_r (16-bit UTMI @30 MHz); 0=DWC_USB3_HSPHY_DWIDTH_0_r (8-bit UTMI @60 MHz)
  [5:4] DWC_USB3_FSPHY_INTERFACE — Global hardware configuration parameter DWC_USB3_FSPHY_INTERFACE: Full (/Low)-Speed (serial) PHY interface
    0=none (No FS/LS PHY i/f)
  [3:2] DWC_USB3_HSPHY_INTERFACE — Global hardware configuration parameter DWC_USB3_HSPHY_INTERFACE: High-speed PHY interface
    3=both (UTMI+ and ULPI i/f (mutually exclusive operation)); 2=ULPI i/f; 1=UTMI+ i/f; 0=none (No HS (/FS/LS) PHY i/f)
  [1:0] DWC_USB3_SSPHY_INTERFACE — Global hardware configuration parameter DWC_USB3_SSPHY_INTERFACE: Super Speed PHY interface.
    1=PIPE i/f for USB3.0; 0=none (No SS PHY i/f)
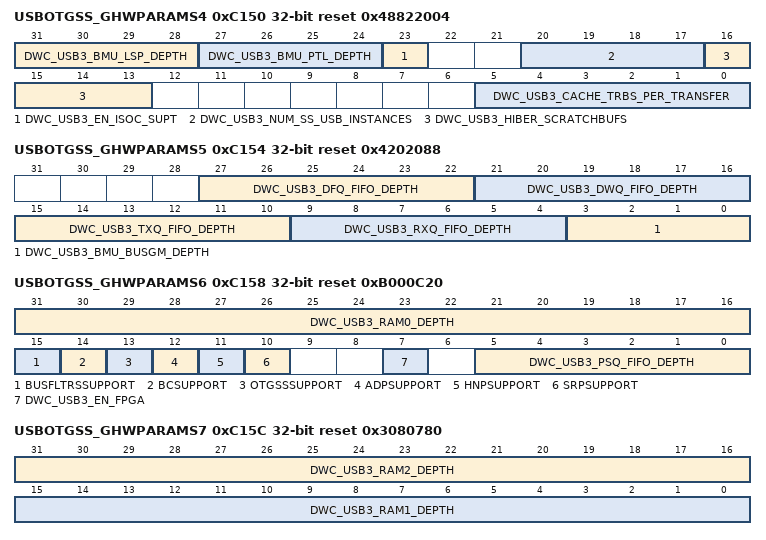
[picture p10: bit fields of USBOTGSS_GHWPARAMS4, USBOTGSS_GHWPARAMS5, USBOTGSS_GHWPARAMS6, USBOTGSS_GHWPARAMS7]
0xC150 USBOTGSS_GHWPARAMS4 ro reset 0x48822004 — Global hardware parameters 4
  [31:28] DWC_USB3_BMU_LSP_DEPTH — Global hardware configuration parameter DWC_USB3_BMU_LSP_DEPTH: Bus Management Unit / List Processor buffer depth
  [27:24] DWC_USB3_BMU_PTL_DEPTH — Global hardware configuration parameter DWC_USB3_BMU_PTL_DEPTH: Bus Management Unit / Protocol Transaction Layer buffer depth
  [23] DWC_USB3_EN_ISOC_SUPT — Global hardware configuration parameter DWC_USB3_EN_ISOC_SUPT: Enable Isochronous Support
    1=iso (Isochronous transfer type supported); 0=none (Isochronous not supported)
  [20:17] DWC_USB3_NUM_SS_USB_INSTANCES — Global hardware configuration parameter DWC_USB3_NUM_SS_USB_INSTANCES: Number of (independent) SS USB schedulers
  [16:13] DWC_USB3_HIBER_SCRATCHBUFS — Global hardware configuration parameter DWC_USB3_HIBER_SCRATCHBUFS: Number of 4-kbyte buffers required in system memory to store context during hibernation. Don't care since hibernation is not enabled.
  [5:0] DWC_USB3_CACHE_TRBS_PER_TRANSFER — Global hardware configuration parameter DWC_USB3_CACHE_TRBS_PER_TRANSFER
0xC154 USBOTGSS_GHWPARAMS5 ro reset 0x4202088 — Global hardware parameters 5
  [27:22] DWC_USB3_DFQ_FIFO_DEPTH — Global hardware configuration parameter DWC_USB3_DFQ_FIFO_DEPTH
  [21:16] DWC_USB3_DWQ_FIFO_DEPTH — Global hardware configuration parameter DWC_USB3_DWQ_FIFO_DEPTH
  [15:10] DWC_USB3_TXQ_FIFO_DEPTH — Global hardware configuration parameter DWC_USB3_TXQ_FIFO_DEPTH
  [9:4] DWC_USB3_RXQ_FIFO_DEPTH — Global hardware configuration parameter DWC_USB3_RXQ_FIFO_DEPTH
  [3:0] DWC_USB3_BMU_BUSGM_DEPTH — Global hardware configuration parameter DWC_USB3_BMU_BUSGM_DEPTH
0xC158 USBOTGSS_GHWPARAMS6 ro reset 0xB000C20 — Global hardware parameters 6
  [31:16] DWC_USB3_RAM0_DEPTH — Depth of RAM 0, in 64-bit words. RAM0 contains data cache and Rx FIFOs.
  [15] BUSFLTRSSUPPORT — Filtering (debounce) on OTG UTMI+ inputs (iddig,vbusvalid,avalid,bvalid,sessend). Reflects DWC_USB3_EN_OTG_FILTERS.
    1=imp (Implemented); 0=no (Not implemented)
  [14] BCSUPPORT — Battery Charger detection (ACA = Accessory Charger Adapter) support implemented internally. Reflects DWC_USB3_EN_BC. Note: Support can also be provided OUTSIDE the controller.
    1=imp (ACA supported by internal logic); 0=no (ACA not supported, or supported by external logic)
  [13] OTGSSSUPPORT — OTG SuperSpeed support (aka OTG3.0)
    1=yes (OTG3.0 supported); 0=no (OTG3.0 not supported)
  [12] ADPSUPPORT — OTG2.0 ADP (Attach Detection Protocol) support implemented internally. Reflects DWC_USB3_EN_ADP. Note: Support can also be provided OUTSIDE the controller.
    1=imp (ADP supported by internal logic); 0=no (ADP not supported, or supported by external logic)
  [11] HNPSUPPORT — OTG2.0 HNP (Host Negotiation Protocol) support. Set when in DRD mode.
    1=Supported; 0=no (Not supported)
  [10] SRPSUPPORT — OTG2.0 SRP (Session Request Protocol) support.
    1=Supported; 0=no (Not supported)
  [7] DWC_USB3_EN_FPGA — Global hardware configuration parameter DWC_USB3_EN_FPGA
  [5:0] DWC_USB3_PSQ_FIFO_DEPTH — Global hardware configuration parameter DWC_USB3_PSQ_FIFO_DEPTH
0xC15C USBOTGSS_GHWPARAMS7 ro reset 0x3080780 — Global hardware parameters 7
  [31:16] DWC_USB3_RAM2_DEPTH — Depth of RAM 2, in 64-bit words. RAM2 IS NOT IMPLEMENTED IN 2-RAM CONFIG: don't care
  [15:0] DWC_USB3_RAM1_DEPTH — Depth of RAM 1, in 64-bit words. RAM1 contains Tx FIFOs.
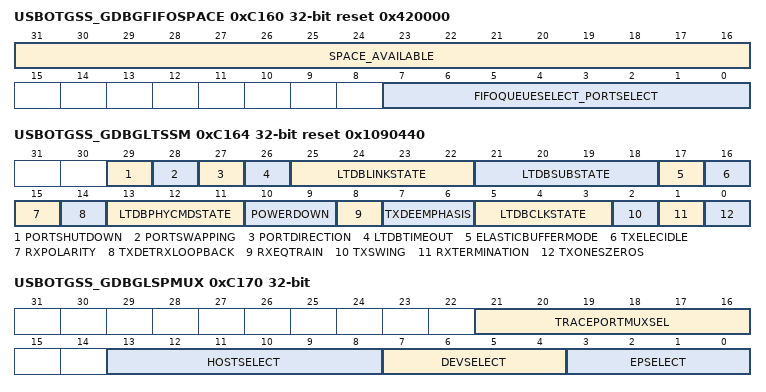
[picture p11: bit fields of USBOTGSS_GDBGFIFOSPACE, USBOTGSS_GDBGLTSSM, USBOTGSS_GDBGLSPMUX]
0xC160 USBOTGSS_GDBGFIFOSPACE access per field reset 0x420000 — Global debug FIFO/queue space available
  [31:16] SPACE_AVAILABLE ro — Space available (in the selected FIFO/queue), 64-bit words
  [7:0] FIFOQUEUESELECT_PORTSELECT rw — FIFO/queue select or port select. Default value, when indicated, is the space available when empty, that is, the size of the FIFO/queue. PORTSELECT[3:0] selects the port number when accessing the USBOTGSS_GDBGLTSSM register. FIFOQUEUESELECT[7:0]:
    63=RX_FIFO_number_31_=_SELECT-32; 127=RxReqQ_number_31_=_SELECT-96; 161=EventQ; 0=TxFIFO_number_0_=_SELECT; 31=TxFIFO_number_31_=_SELECT; 128=RxInfoQ_number_0_=_SELECT-128; 95=TxReqQ_number_31_=_SELECT-64; 160=DescFetchQ_(default:16); 159=RxInfoQ_number_31_=_SELECT-128; 96=RxReqQ_number_0_=_SELECT-96; 64=TxReqQ_number_0_=_SELECT-64; 32=RxFIFO_number_0_=_SELECT-32; 162=ProtocolStatusQ_(default:_32)
0xC164 USBOTGSS_GDBGLTSSM ro reset 0x1090440 — Global debug LTSSM Port number is defined by [3:0] PORTSELECT
  [29] PORTSHUTDOWN
  [28] PORTSWAPPING
  [27] PORTDIRECTION — Current direction of the port.
    1=DS (Downstream (host) port); 0=US (Upstream (device) port)
  [26] LTDBTIMEOUT — LTSSM Debug Timeout
  [25:22] LTDBLINKSTATE — LTSSM Debug: Link State
    3=U3 (U3 low-power state); 4=SSdisabled; 11=Loopback; 2=U2 (U2 low-power state); 0=U0 (U0 active state); 10=Compliance mode; 6=SSinactive; 1=U1 (U1 low-power state); 8=Recovery; 7=Polling; 9=HotReset; 5=RXdetect
  [21:18] LTDBSUBSTATE — LTSSM Debug: Link Sub-State. Note that the actual reset value (0x0) changes before the register can be read out.
  [17] ELASTICBUFFERMODE — Debug PIPE Status: ElasticBufferMode
  [16] TXELECIDLE — Debug PIPE Status: TxElecIdle
  [15] RXPOLARITY — Debug PIPE Status: RxPolarity
  [14] TXDETRXLOOPBACK — Debug PIPE Status: TxDetRxLoopback
  [13:11] LTDBPHYCMDSTATE — LTSSM Debug Phy Command State.
    3=PHY_PWR_DLY (Delay Pipe_PowerDown P0 -> P1/P2/P3 request); 4=PHY_PWR_A (Delay for internal logic); 2=PHY_DET_3 (Wait for Phy_Status (Receiver detection)); 0=PHY_IDLE (PHY command state is in IDLE. No PHY request pending); 1=PHY_DET (Request to start Receiver detection); 5=PHY_PWR_B (Wait for Phy_Status(Power state change request))
  [10:9] POWERDOWN — Debug PIPE Status: PowerDown
  [8] RXEQTRAIN — Debug PIPE Status: RxEqTrain
  [7:6] TXDEEMPHASIS — Debug PIPE Status: TxDeemphasis
  [5:3] LTDBCLKSTATE — LTSSM Debug Clock State
    3=CLK_P3 (PHY is in P3 and PCLK is not running); 4=CLK_TO_P0 (P3 exit request to PHY); 2=CLK_WAIT1 (Wait for Phy_Status (P3 request)); 0=CLK_NORM (PHY is in non-P3 state and PCLK is running); 1=CLK_TO_P3 (P3 entry request to PHY); 5=CLK_WAIT2 (Wait for Phy_Status (P3 exit request))
  [2] TXSWING — Debug PIPE Status: TxSwing
  [1] RXTERMINATION — Debug PIPE Status: RxTermination
  [0] TXONESZEROS — Debug PIPE Status: TxOnesZeros
0xC170 USBOTGSS_GDBGLSPMUX access per field — Global debug LSP MUX, for internal use only
  [21:16] TRACEPORTMUXSEL rw — Select the 64-bit analyzer trace vector. Not sensitive to warm reset (i.e. including software reset), only to power-on reset.
    63=zero (Trace vector is forced to all-zero)
  [13:8] HOSTSELECT rw — Host LSP Select[13:8]. Valid only in Host mode.
  [7:4] DEVSELECT rw — Host LSP Select[7:4] in Host mode Device LSP Select in Device mode
  [3:0] EPSELECT rw — Host LSP Select[3:0] in Host mode Device LSP Select in Device mode
0xC174 USBOTGSS_GDBGLSP ro — Global debug LSP, for internal use only
  [31:0] DEBUG — LSP debug information
0xC178 USBOTGSS_GDBGEPINFO0 ro — Global debug endpoint information register 0
  [31:0] DEBUG — EP debug information
0xC17C USBOTGSS_GDBGEPINFO1 ro — Global debug endpoint information register 1
  [31:0] DEBUG — EP debug information
0xC180 USBOTGSS_GPRTBIMAP_HSLO access per field — Global port to USB instance mapping register, high-speed, low bits [31:0]
  [3:0] BINUM1 rw — HS USB instance number for port number 1 Application-programmable ID field
0xC184 USBOTGSS_GPRTBIMAP_HSHI ro — Global port to USB instance mapping register, high-speed, high bits [63:32]
